# ESP32-H4 register map
Vendor: ESPRESSIF SYSTEMS (SHANGHAI) CO., LTD.; Series: ESP32 H-Series; File version: 1
CPU: RV32IMAC r0p0, little endian, no MPU, no FPU, 0 interrupt priority bits
Address unit: 32 bits
Registers are 32-bit, read-write, reset 0x0 unless marked. A register's access mark holds for its fields unless they carry their own. Offsets are from the block's base; [hi:lo] are bit positions; {n}, {i} and the like mark numbered series.

## SOC_ETM (part 1 of 2) — Event Task Matrix
Base 0x60021000
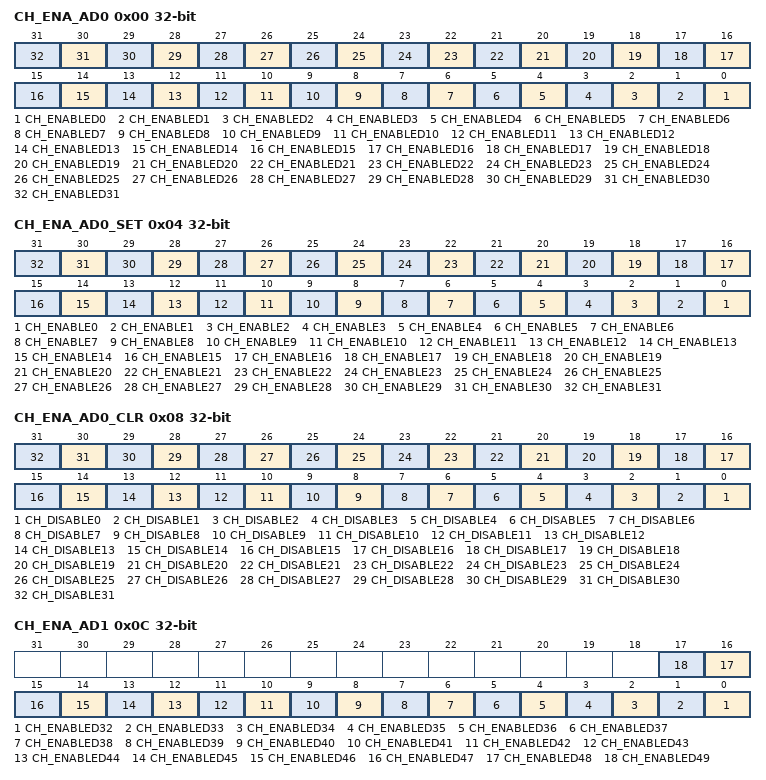
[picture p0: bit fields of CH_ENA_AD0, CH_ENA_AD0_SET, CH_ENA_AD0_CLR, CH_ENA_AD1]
0x00 CH_ENA_AD0 — Channel enable status register
  [n] CH_ENABLED{n} (n=0..31) — Represents ch{n} enable status.\\0: Disable\\1: Enable
0x04 CH_ENA_AD0_SET wo — Channel enable set register
  [n] CH_ENABLE{n} (n=0..31) — Configures whether or not to enable ch{n}.\\0: Invalid, No effect\\1: Enable
0x08 CH_ENA_AD0_CLR wo — Channel enable clear register
  [n] CH_DISABLE{n} (n=0..31) — Configures whether or not to clear ch{n} enable.\\0: Invalid, No effect\\1: Clear
0x0C CH_ENA_AD1 — Channel enable status register
  [n-32] CH_ENABLED{n} (n=32..49) — Represents ch{n} enable status.\\0: Disable\\1: Enable
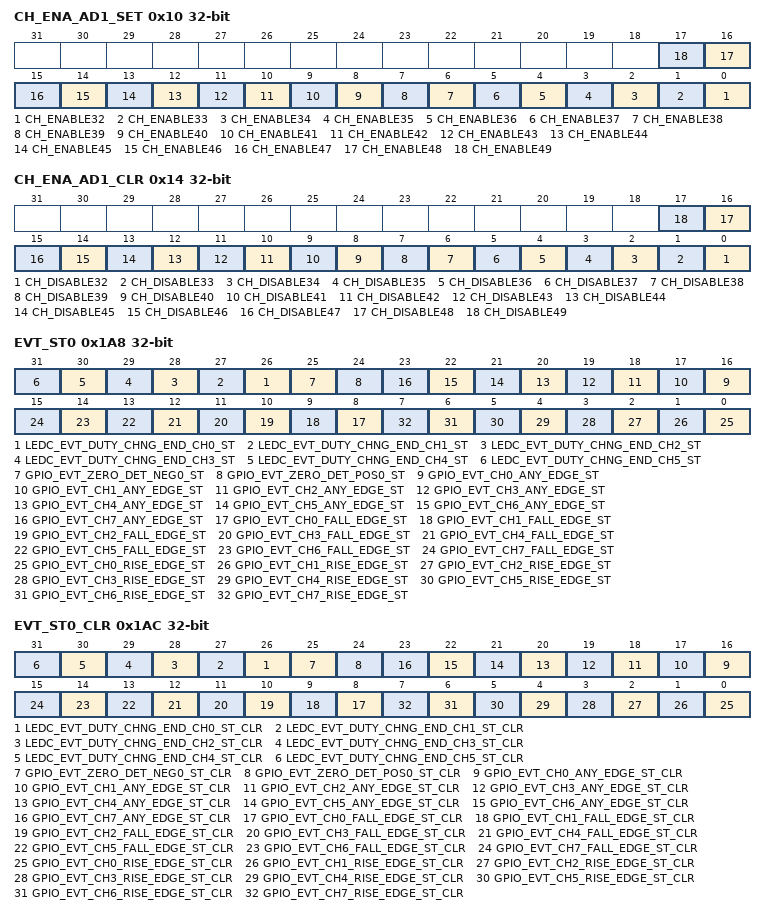
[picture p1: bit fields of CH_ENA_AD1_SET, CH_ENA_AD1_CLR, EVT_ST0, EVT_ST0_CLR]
0x10 CH_ENA_AD1_SET wo — Channel enable set register
  [n-32] CH_ENABLE{n} (n=32..49) — Configures whether or not to enable ch{n}.\\0: Invalid, No effect\\1: Enable
0x14 CH_ENA_AD1_CLR wo — Channel enable clear register
  [n-32] CH_DISABLE{n} (n=32..49) — Configures whether or not to clear ch{n} enable.\\0: Invalid, No effect\\1: Clear
{0x18+8i} CH{i}_EVT_ID (i=0..49) — Channel{i} event id register
  [7:0] CH_EVT_ID — Configures ch%s_evt_id
{0x1C+8i} CH{i}_TASK_ID (i=0..49) — Channel{i} task id register
  [7:0] CH_TASK_ID — Configures ch%s_task_id
0x1A8 EVT_ST0 — Events trigger status register
  [n+26] LEDC_EVT_DUTY_CHNG_END_CH{n}_ST (n=0..5) — Represents LEDC_evt_duty_chng_end_ch{n} trigger status.\\0: Not triggered\\1: Triggered
  [25] GPIO_EVT_ZERO_DET_NEG0_ST — Represents GPIO_evt_zero_det_neg0 trigger status.\\0: Not triggered\\1: Triggered
  [24] GPIO_EVT_ZERO_DET_POS0_ST — Represents GPIO_evt_zero_det_pos0 trigger status.\\0: Not triggered\\1: Triggered
  [n+16] GPIO_EVT_CH{n}_ANY_EDGE_ST (n=0..7) — Represents GPIO_evt_ch{n}_any_edge trigger status.\\0: Not triggered\\1: Triggered
  [n+8] GPIO_EVT_CH{n}_FALL_EDGE_ST (n=0..7) — Represents GPIO_evt_ch{n}_fall_edge trigger status.\\0: Not triggered\\1: Triggered
  [n] GPIO_EVT_CH{n}_RISE_EDGE_ST (n=0..7) — Represents GPIO_evt_ch{n}_rise_edge trigger status.\\0: Not triggered\\1: Triggered
0x1AC EVT_ST0_CLR wo — Events trigger status clear register
  [n+26] LEDC_EVT_DUTY_CHNG_END_CH{n}_ST_CLR (n=0..5) — Configures whether or not to clear LEDC_evt_duty_chng_end_ch{n} trigger status.\\0: Invalid, No effect\\1: Clear
  [25] GPIO_EVT_ZERO_DET_NEG0_ST_CLR — Configures whether or not to clear GPIO_evt_zero_det_neg0 trigger status.\\0: Invalid, No effect\\1: Clear
  [24] GPIO_EVT_ZERO_DET_POS0_ST_CLR — Configures whether or not to clear GPIO_evt_zero_det_pos0 trigger status.\\0: Invalid, No effect\\1: Clear
  [n+16] GPIO_EVT_CH{n}_ANY_EDGE_ST_CLR (n=0..7) — Configures whether or not to clear GPIO_evt_ch{n}_any_edge trigger status.\\0: Invalid, No effect\\1: Clear
  [n+8] GPIO_EVT_CH{n}_FALL_EDGE_ST_CLR (n=0..7) — Configures whether or not to clear GPIO_evt_ch{n}_fall_edge trigger status.\\0: Invalid, No effect\\1: Clear
  [n] GPIO_EVT_CH{n}_RISE_EDGE_ST_CLR (n=0..7) — Configures whether or not to clear GPIO_evt_ch{n}_rise_edge trigger status.\\0: Invalid, No effect\\1: Clear
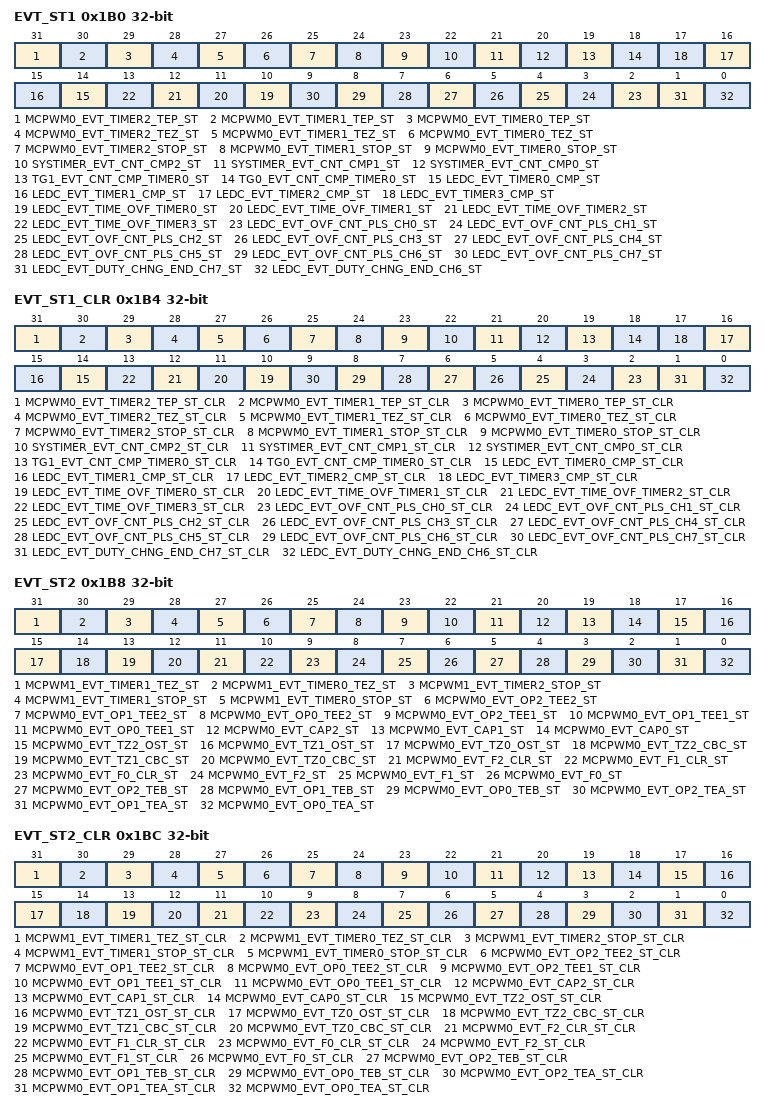
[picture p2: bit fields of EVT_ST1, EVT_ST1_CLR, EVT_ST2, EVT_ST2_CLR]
0x1B0 EVT_ST1 — Events trigger status register
  [31] MCPWM0_EVT_TIMER2_TEP_ST — Represents MCPWM0_evt_timer2_tep trigger status.\\0: Not triggered\\1: Triggered
  [30] MCPWM0_EVT_TIMER1_TEP_ST — Represents MCPWM0_evt_timer1_tep trigger status.\\0: Not triggered\\1: Triggered
  [29] MCPWM0_EVT_TIMER0_TEP_ST — Represents MCPWM0_evt_timer0_tep trigger status.\\0: Not triggered\\1: Triggered
  [28] MCPWM0_EVT_TIMER2_TEZ_ST — Represents MCPWM0_evt_timer2_tez trigger status.\\0: Not triggered\\1: Triggered
  [27] MCPWM0_EVT_TIMER1_TEZ_ST — Represents MCPWM0_evt_timer1_tez trigger status.\\0: Not triggered\\1: Triggered
  [26] MCPWM0_EVT_TIMER0_TEZ_ST — Represents MCPWM0_evt_timer0_tez trigger status.\\0: Not triggered\\1: Triggered
  [25] MCPWM0_EVT_TIMER2_STOP_ST — Represents MCPWM0_evt_timer2_stop trigger status.\\0: Not triggered\\1: Triggered
  [24] MCPWM0_EVT_TIMER1_STOP_ST — Represents MCPWM0_evt_timer1_stop trigger status.\\0: Not triggered\\1: Triggered
  [23] MCPWM0_EVT_TIMER0_STOP_ST — Represents MCPWM0_evt_timer0_stop trigger status.\\0: Not triggered\\1: Triggered
  [22] SYSTIMER_EVT_CNT_CMP2_ST — Represents SYSTIMER_evt_cnt_cmp2 trigger status.\\0: Not triggered\\1: Triggered
  [21] SYSTIMER_EVT_CNT_CMP1_ST — Represents SYSTIMER_evt_cnt_cmp1 trigger status.\\0: Not triggered\\1: Triggered
  [20] SYSTIMER_EVT_CNT_CMP0_ST — Represents SYSTIMER_evt_cnt_cmp0 trigger status.\\0: Not triggered\\1: Triggered
  [19] TG1_EVT_CNT_CMP_TIMER0_ST — Represents TG1_evt_cnt_cmp_timer0 trigger status.\\0: Not triggered\\1: Triggered
  [18] TG0_EVT_CNT_CMP_TIMER0_ST — Represents TG0_evt_cnt_cmp_timer0 trigger status.\\0: Not triggered\\1: Triggered
  [n+14] LEDC_EVT_TIMER{n}_CMP_ST (n=0..3) — Represents LEDC_evt_timer{n}_cmp trigger status.\\0: Not triggered\\1: Triggered
  [n+10] LEDC_EVT_TIME_OVF_TIMER{n}_ST (n=0..3) — Represents LEDC_evt_time_ovf_timer{n} trigger status.\\0: Not triggered\\1: Triggered
  [n+2] LEDC_EVT_OVF_CNT_PLS_CH{n}_ST (n=0..7) — Represents LEDC_evt_ovf_cnt_pls_ch{n} trigger status.\\0: Not triggered\\1: Triggered
  [1] LEDC_EVT_DUTY_CHNG_END_CH7_ST — Represents LEDC_evt_duty_chng_end_ch7 trigger status.\\0: Not triggered\\1: Triggered
  [0] LEDC_EVT_DUTY_CHNG_END_CH6_ST — Represents LEDC_evt_duty_chng_end_ch6 trigger status.\\0: Not triggered\\1: Triggered
0x1B4 EVT_ST1_CLR wo — Events trigger status clear register
  [31] MCPWM0_EVT_TIMER2_TEP_ST_CLR — Configures whether or not to clear MCPWM0_evt_timer2_tep trigger status.\\0: Invalid, No effect\\1: Clear
  [30] MCPWM0_EVT_TIMER1_TEP_ST_CLR — Configures whether or not to clear MCPWM0_evt_timer1_tep trigger status.\\0: Invalid, No effect\\1: Clear
  [29] MCPWM0_EVT_TIMER0_TEP_ST_CLR — Configures whether or not to clear MCPWM0_evt_timer0_tep trigger status.\\0: Invalid, No effect\\1: Clear
  [28] MCPWM0_EVT_TIMER2_TEZ_ST_CLR — Configures whether or not to clear MCPWM0_evt_timer2_tez trigger status.\\0: Invalid, No effect\\1: Clear
  [27] MCPWM0_EVT_TIMER1_TEZ_ST_CLR — Configures whether or not to clear MCPWM0_evt_timer1_tez trigger status.\\0: Invalid, No effect\\1: Clear
  [26] MCPWM0_EVT_TIMER0_TEZ_ST_CLR — Configures whether or not to clear MCPWM0_evt_timer0_tez trigger status.\\0: Invalid, No effect\\1: Clear
  [25] MCPWM0_EVT_TIMER2_STOP_ST_CLR — Configures whether or not to clear MCPWM0_evt_timer2_stop trigger status.\\0: Invalid, No effect\\1: Clear
  [24] MCPWM0_EVT_TIMER1_STOP_ST_CLR — Configures whether or not to clear MCPWM0_evt_timer1_stop trigger status.\\0: Invalid, No effect\\1: Clear
  [23] MCPWM0_EVT_TIMER0_STOP_ST_CLR — Configures whether or not to clear MCPWM0_evt_timer0_stop trigger status.\\0: Invalid, No effect\\1: Clear
  [22] SYSTIMER_EVT_CNT_CMP2_ST_CLR — Configures whether or not to clear SYSTIMER_evt_cnt_cmp2 trigger status.\\0: Invalid, No effect\\1: Clear
  [21] SYSTIMER_EVT_CNT_CMP1_ST_CLR — Configures whether or not to clear SYSTIMER_evt_cnt_cmp1 trigger status.\\0: Invalid, No effect\\1: Clear
  [20] SYSTIMER_EVT_CNT_CMP0_ST_CLR — Configures whether or not to clear SYSTIMER_evt_cnt_cmp0 trigger status.\\0: Invalid, No effect\\1: Clear
  [19] TG1_EVT_CNT_CMP_TIMER0_ST_CLR — Configures whether or not to clear TG1_evt_cnt_cmp_timer0 trigger status.\\0: Invalid, No effect\\1: Clear
  [18] TG0_EVT_CNT_CMP_TIMER0_ST_CLR — Configures whether or not to clear TG0_evt_cnt_cmp_timer0 trigger status.\\0: Invalid, No effect\\1: Clear
  [n+14] LEDC_EVT_TIMER{n}_CMP_ST_CLR (n=0..3) — Configures whether or not to clear LEDC_evt_timer{n}_cmp trigger status.\\0: Invalid, No effect\\1: Clear
  [n+10] LEDC_EVT_TIME_OVF_TIMER{n}_ST_CLR (n=0..3) — Configures whether or not to clear LEDC_evt_time_ovf_timer{n} trigger status.\\0: Invalid, No effect\\1: Clear
  [n+2] LEDC_EVT_OVF_CNT_PLS_CH{n}_ST_CLR (n=0..7) — Configures whether or not to clear LEDC_evt_ovf_cnt_pls_ch{n} trigger status.\\0: Invalid, No effect\\1: Clear
  [1] LEDC_EVT_DUTY_CHNG_END_CH7_ST_CLR — Configures whether or not to clear LEDC_evt_duty_chng_end_ch7 trigger status.\\0: Invalid, No effect\\1: Clear
  [0] LEDC_EVT_DUTY_CHNG_END_CH6_ST_CLR — Configures whether or not to clear LEDC_evt_duty_chng_end_ch6 trigger status.\\0: Invalid, No effect\\1: Clear
0x1B8 EVT_ST2 — Events trigger status register
  [31] MCPWM1_EVT_TIMER1_TEZ_ST — Represents MCPWM1_evt_timer1_tez trigger status.\\0: Not triggered\\1: Triggered
  [30] MCPWM1_EVT_TIMER0_TEZ_ST — Represents MCPWM1_evt_timer0_tez trigger status.\\0: Not triggered\\1: Triggered
  [29] MCPWM1_EVT_TIMER2_STOP_ST — Represents MCPWM1_evt_timer2_stop trigger status.\\0: Not triggered\\1: Triggered
  [28] MCPWM1_EVT_TIMER1_STOP_ST — Represents MCPWM1_evt_timer1_stop trigger status.\\0: Not triggered\\1: Triggered
  [27] MCPWM1_EVT_TIMER0_STOP_ST — Represents MCPWM1_evt_timer0_stop trigger status.\\0: Not triggered\\1: Triggered
  [26] MCPWM0_EVT_OP2_TEE2_ST — Represents MCPWM0_evt_op2_tee2 trigger status.\\0: Not triggered\\1: Triggered
  [25] MCPWM0_EVT_OP1_TEE2_ST — Represents MCPWM0_evt_op1_tee2 trigger status.\\0: Not triggered\\1: Triggered
  [24] MCPWM0_EVT_OP0_TEE2_ST — Represents MCPWM0_evt_op0_tee2 trigger status.\\0: Not triggered\\1: Triggered
  [23] MCPWM0_EVT_OP2_TEE1_ST — Represents MCPWM0_evt_op2_tee1 trigger status.\\0: Not triggered\\1: Triggered
  [22] MCPWM0_EVT_OP1_TEE1_ST — Represents MCPWM0_evt_op1_tee1 trigger status.\\0: Not triggered\\1: Triggered
  [21] MCPWM0_EVT_OP0_TEE1_ST — Represents MCPWM0_evt_op0_tee1 trigger status.\\0: Not triggered\\1: Triggered
  [20] MCPWM0_EVT_CAP2_ST — Represents MCPWM0_evt_cap2 trigger status.\\0: Not triggered\\1: Triggered
  [19] MCPWM0_EVT_CAP1_ST — Represents MCPWM0_evt_cap1 trigger status.\\0: Not triggered\\1: Triggered
  [18] MCPWM0_EVT_CAP0_ST — Represents MCPWM0_evt_cap0 trigger status.\\0: Not triggered\\1: Triggered
  [17] MCPWM0_EVT_TZ2_OST_ST — Represents MCPWM0_evt_tz2_ost trigger status.\\0: Not triggered\\1: Triggered
  [16] MCPWM0_EVT_TZ1_OST_ST — Represents MCPWM0_evt_tz1_ost trigger status.\\0: Not triggered\\1: Triggered
  [15] MCPWM0_EVT_TZ0_OST_ST — Represents MCPWM0_evt_tz0_ost trigger status.\\0: Not triggered\\1: Triggered
  [14] MCPWM0_EVT_TZ2_CBC_ST — Represents MCPWM0_evt_tz2_cbc trigger status.\\0: Not triggered\\1: Triggered
  [13] MCPWM0_EVT_TZ1_CBC_ST — Represents MCPWM0_evt_tz1_cbc trigger status.\\0: Not triggered\\1: Triggered
  [12] MCPWM0_EVT_TZ0_CBC_ST — Represents MCPWM0_evt_tz0_cbc trigger status.\\0: Not triggered\\1: Triggered
  [11] MCPWM0_EVT_F2_CLR_ST — Represents MCPWM0_evt_f2_clr trigger status.\\0: Not triggered\\1: Triggered
  [10] MCPWM0_EVT_F1_CLR_ST — Represents MCPWM0_evt_f1_clr trigger status.\\0: Not triggered\\1: Triggered
  [9] MCPWM0_EVT_F0_CLR_ST — Represents MCPWM0_evt_f0_clr trigger status.\\0: Not triggered\\1: Triggered
  [8] MCPWM0_EVT_F2_ST — Represents MCPWM0_evt_f2 trigger status.\\0: Not triggered\\1: Triggered
  [7] MCPWM0_EVT_F1_ST — Represents MCPWM0_evt_f1 trigger status.\\0: Not triggered\\1: Triggered
  [6] MCPWM0_EVT_F0_ST — Represents MCPWM0_evt_f0 trigger status.\\0: Not triggered\\1: Triggered
  [5] MCPWM0_EVT_OP2_TEB_ST — Represents MCPWM0_evt_op2_teb trigger status.\\0: Not triggered\\1: Triggered
  [4] MCPWM0_EVT_OP1_TEB_ST — Represents MCPWM0_evt_op1_teb trigger status.\\0: Not triggered\\1: Triggered
  [3] MCPWM0_EVT_OP0_TEB_ST — Represents MCPWM0_evt_op0_teb trigger status.\\0: Not triggered\\1: Triggered
  [2] MCPWM0_EVT_OP2_TEA_ST — Represents MCPWM0_evt_op2_tea trigger status.\\0: Not triggered\\1: Triggered
  [1] MCPWM0_EVT_OP1_TEA_ST — Represents MCPWM0_evt_op1_tea trigger status.\\0: Not triggered\\1: Triggered
  [0] MCPWM0_EVT_OP0_TEA_ST — Represents MCPWM0_evt_op0_tea trigger status.\\0: Not triggered\\1: Triggered
0x1BC EVT_ST2_CLR wo — Events trigger status clear register
  [31] MCPWM1_EVT_TIMER1_TEZ_ST_CLR — Configures whether or not to clear MCPWM1_evt_timer1_tez trigger status.\\0: Invalid, No effect\\1: Clear
  [30] MCPWM1_EVT_TIMER0_TEZ_ST_CLR — Configures whether or not to clear MCPWM1_evt_timer0_tez trigger status.\\0: Invalid, No effect\\1: Clear
  [29] MCPWM1_EVT_TIMER2_STOP_ST_CLR — Configures whether or not to clear MCPWM1_evt_timer2_stop trigger status.\\0: Invalid, No effect\\1: Clear
  [28] MCPWM1_EVT_TIMER1_STOP_ST_CLR — Configures whether or not to clear MCPWM1_evt_timer1_stop trigger status.\\0: Invalid, No effect\\1: Clear
  [27] MCPWM1_EVT_TIMER0_STOP_ST_CLR — Configures whether or not to clear MCPWM1_evt_timer0_stop trigger status.\\0: Invalid, No effect\\1: Clear
  [26] MCPWM0_EVT_OP2_TEE2_ST_CLR — Configures whether or not to clear MCPWM0_evt_op2_tee2 trigger status.\\0: Invalid, No effect\\1: Clear
  [25] MCPWM0_EVT_OP1_TEE2_ST_CLR — Configures whether or not to clear MCPWM0_evt_op1_tee2 trigger status.\\0: Invalid, No effect\\1: Clear
  [24] MCPWM0_EVT_OP0_TEE2_ST_CLR — Configures whether or not to clear MCPWM0_evt_op0_tee2 trigger status.\\0: Invalid, No effect\\1: Clear
  [23] MCPWM0_EVT_OP2_TEE1_ST_CLR — Configures whether or not to clear MCPWM0_evt_op2_tee1 trigger status.\\0: Invalid, No effect\\1: Clear
  [22] MCPWM0_EVT_OP1_TEE1_ST_CLR — Configures whether or not to clear MCPWM0_evt_op1_tee1 trigger status.\\0: Invalid, No effect\\1: Clear
  [21] MCPWM0_EVT_OP0_TEE1_ST_CLR — Configures whether or not to clear MCPWM0_evt_op0_tee1 trigger status.\\0: Invalid, No effect\\1: Clear
  [20] MCPWM0_EVT_CAP2_ST_CLR — Configures whether or not to clear MCPWM0_evt_cap2 trigger status.\\0: Invalid, No effect\\1: Clear
  [19] MCPWM0_EVT_CAP1_ST_CLR — Configures whether or not to clear MCPWM0_evt_cap1 trigger status.\\0: Invalid, No effect\\1: Clear
  [18] MCPWM0_EVT_CAP0_ST_CLR — Configures whether or not to clear MCPWM0_evt_cap0 trigger status.\\0: Invalid, No effect\\1: Clear
  [17] MCPWM0_EVT_TZ2_OST_ST_CLR — Configures whether or not to clear MCPWM0_evt_tz2_ost trigger status.\\0: Invalid, No effect\\1: Clear
  [16] MCPWM0_EVT_TZ1_OST_ST_CLR — Configures whether or not to clear MCPWM0_evt_tz1_ost trigger status.\\0: Invalid, No effect\\1: Clear
  [15] MCPWM0_EVT_TZ0_OST_ST_CLR — Configures whether or not to clear MCPWM0_evt_tz0_ost trigger status.\\0: Invalid, No effect\\1: Clear
  [14] MCPWM0_EVT_TZ2_CBC_ST_CLR — Configures whether or not to clear MCPWM0_evt_tz2_cbc trigger status.\\0: Invalid, No effect\\1: Clear
  [13] MCPWM0_EVT_TZ1_CBC_ST_CLR — Configures whether or not to clear MCPWM0_evt_tz1_cbc trigger status.\\0: Invalid, No effect\\1: Clear
  [12] MCPWM0_EVT_TZ0_CBC_ST_CLR — Configures whether or not to clear MCPWM0_evt_tz0_cbc trigger status.\\0: Invalid, No effect\\1: Clear
  [11] MCPWM0_EVT_F2_CLR_ST_CLR — Configures whether or not to clear MCPWM0_evt_f2_clr trigger status.\\0: Invalid, No effect\\1: Clear
  [10] MCPWM0_EVT_F1_CLR_ST_CLR — Configures whether or not to clear MCPWM0_evt_f1_clr trigger status.\\0: Invalid, No effect\\1: Clear
  [9] MCPWM0_EVT_F0_CLR_ST_CLR — Configures whether or not to clear MCPWM0_evt_f0_clr trigger status.\\0: Invalid, No effect\\1: Clear
  [8] MCPWM0_EVT_F2_ST_CLR — Configures whether or not to clear MCPWM0_evt_f2 trigger status.\\0: Invalid, No effect\\1: Clear
  [7] MCPWM0_EVT_F1_ST_CLR — Configures whether or not to clear MCPWM0_evt_f1 trigger status.\\0: Invalid, No effect\\1: Clear
  [6] MCPWM0_EVT_F0_ST_CLR — Configures whether or not to clear MCPWM0_evt_f0 trigger status.\\0: Invalid, No effect\\1: Clear
  [5] MCPWM0_EVT_OP2_TEB_ST_CLR — Configures whether or not to clear MCPWM0_evt_op2_teb trigger status.\\0: Invalid, No effect\\1: Clear
  [4] MCPWM0_EVT_OP1_TEB_ST_CLR — Configures whether or not to clear MCPWM0_evt_op1_teb trigger status.\\0: Invalid, No effect\\1: Clear
  [3] MCPWM0_EVT_OP0_TEB_ST_CLR — Configures whether or not to clear MCPWM0_evt_op0_teb trigger status.\\0: Invalid, No effect\\1: Clear
  [2] MCPWM0_EVT_OP2_TEA_ST_CLR — Configures whether or not to clear MCPWM0_evt_op2_tea trigger status.\\0: Invalid, No effect\\1: Clear
  [1] MCPWM0_EVT_OP1_TEA_ST_CLR — Configures whether or not to clear MCPWM0_evt_op1_tea trigger status.\\0: Invalid, No effect\\1: Clear
  [0] MCPWM0_EVT_OP0_TEA_ST_CLR — Configures whether or not to clear MCPWM0_evt_op0_tea trigger status.\\0: Invalid, No effect\\1: Clear
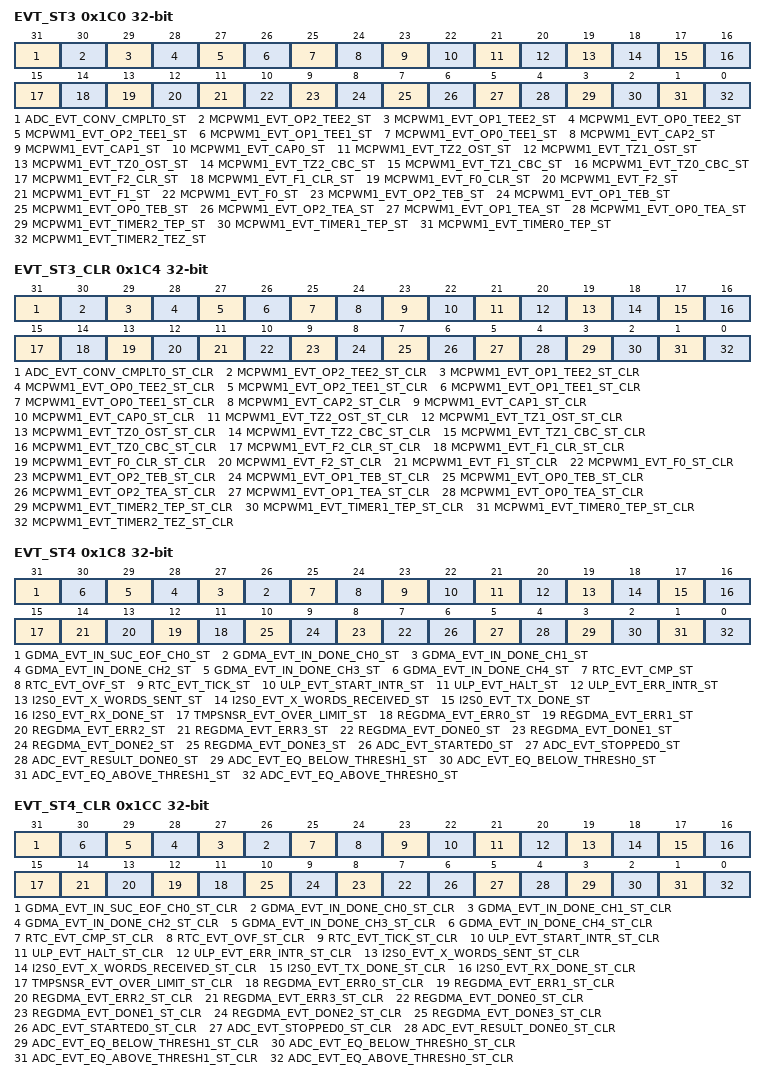
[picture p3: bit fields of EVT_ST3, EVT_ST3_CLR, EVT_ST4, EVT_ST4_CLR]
0x1C0 EVT_ST3 — Events trigger status register
  [31] ADC_EVT_CONV_CMPLT0_ST — Represents ADC_evt_conv_cmplt0 trigger status.\\0: Not triggered\\1: Triggered
  [30] MCPWM1_EVT_OP2_TEE2_ST — Represents MCPWM1_evt_op2_tee2 trigger status.\\0: Not triggered\\1: Triggered
  [29] MCPWM1_EVT_OP1_TEE2_ST — Represents MCPWM1_evt_op1_tee2 trigger status.\\0: Not triggered\\1: Triggered
  [28] MCPWM1_EVT_OP0_TEE2_ST — Represents MCPWM1_evt_op0_tee2 trigger status.\\0: Not triggered\\1: Triggered
  [27] MCPWM1_EVT_OP2_TEE1_ST — Represents MCPWM1_evt_op2_tee1 trigger status.\\0: Not triggered\\1: Triggered
  [26] MCPWM1_EVT_OP1_TEE1_ST — Represents MCPWM1_evt_op1_tee1 trigger status.\\0: Not triggered\\1: Triggered
  [25] MCPWM1_EVT_OP0_TEE1_ST — Represents MCPWM1_evt_op0_tee1 trigger status.\\0: Not triggered\\1: Triggered
  [24] MCPWM1_EVT_CAP2_ST — Represents MCPWM1_evt_cap2 trigger status.\\0: Not triggered\\1: Triggered
  [23] MCPWM1_EVT_CAP1_ST — Represents MCPWM1_evt_cap1 trigger status.\\0: Not triggered\\1: Triggered
  [22] MCPWM1_EVT_CAP0_ST — Represents MCPWM1_evt_cap0 trigger status.\\0: Not triggered\\1: Triggered
  [21] MCPWM1_EVT_TZ2_OST_ST — Represents MCPWM1_evt_tz2_ost trigger status.\\0: Not triggered\\1: Triggered
  [20] MCPWM1_EVT_TZ1_OST_ST — Represents MCPWM1_evt_tz1_ost trigger status.\\0: Not triggered\\1: Triggered
  [19] MCPWM1_EVT_TZ0_OST_ST — Represents MCPWM1_evt_tz0_ost trigger status.\\0: Not triggered\\1: Triggered
  [18] MCPWM1_EVT_TZ2_CBC_ST — Represents MCPWM1_evt_tz2_cbc trigger status.\\0: Not triggered\\1: Triggered
  [17] MCPWM1_EVT_TZ1_CBC_ST — Represents MCPWM1_evt_tz1_cbc trigger status.\\0: Not triggered\\1: Triggered
  [16] MCPWM1_EVT_TZ0_CBC_ST — Represents MCPWM1_evt_tz0_cbc trigger status.\\0: Not triggered\\1: Triggered
  [15] MCPWM1_EVT_F2_CLR_ST — Represents MCPWM1_evt_f2_clr trigger status.\\0: Not triggered\\1: Triggered
  [14] MCPWM1_EVT_F1_CLR_ST — Represents MCPWM1_evt_f1_clr trigger status.\\0: Not triggered\\1: Triggered
  [13] MCPWM1_EVT_F0_CLR_ST — Represents MCPWM1_evt_f0_clr trigger status.\\0: Not triggered\\1: Triggered
  [12] MCPWM1_EVT_F2_ST — Represents MCPWM1_evt_f2 trigger status.\\0: Not triggered\\1: Triggered
  [11] MCPWM1_EVT_F1_ST — Represents MCPWM1_evt_f1 trigger status.\\0: Not triggered\\1: Triggered
  [10] MCPWM1_EVT_F0_ST — Represents MCPWM1_evt_f0 trigger status.\\0: Not triggered\\1: Triggered
  [9] MCPWM1_EVT_OP2_TEB_ST — Represents MCPWM1_evt_op2_teb trigger status.\\0: Not triggered\\1: Triggered
  [8] MCPWM1_EVT_OP1_TEB_ST — Represents MCPWM1_evt_op1_teb trigger status.\\0: Not triggered\\1: Triggered
  [7] MCPWM1_EVT_OP0_TEB_ST — Represents MCPWM1_evt_op0_teb trigger status.\\0: Not triggered\\1: Triggered
  [6] MCPWM1_EVT_OP2_TEA_ST — Represents MCPWM1_evt_op2_tea trigger status.\\0: Not triggered\\1: Triggered
  [5] MCPWM1_EVT_OP1_TEA_ST — Represents MCPWM1_evt_op1_tea trigger status.\\0: Not triggered\\1: Triggered
  [4] MCPWM1_EVT_OP0_TEA_ST — Represents MCPWM1_evt_op0_tea trigger status.\\0: Not triggered\\1: Triggered
  [3] MCPWM1_EVT_TIMER2_TEP_ST — Represents MCPWM1_evt_timer2_tep trigger status.\\0: Not triggered\\1: Triggered
  [2] MCPWM1_EVT_TIMER1_TEP_ST — Represents MCPWM1_evt_timer1_tep trigger status.\\0: Not triggered\\1: Triggered
  [1] MCPWM1_EVT_TIMER0_TEP_ST — Represents MCPWM1_evt_timer0_tep trigger status.\\0: Not triggered\\1: Triggered
  [0] MCPWM1_EVT_TIMER2_TEZ_ST — Represents MCPWM1_evt_timer2_tez trigger status.\\0: Not triggered\\1: Triggered
0x1C4 EVT_ST3_CLR wo — Events trigger status clear register
  [31] ADC_EVT_CONV_CMPLT0_ST_CLR — Configures whether or not to clear ADC_evt_conv_cmplt0 trigger status.\\0: Invalid, No effect\\1: Clear
  [30] MCPWM1_EVT_OP2_TEE2_ST_CLR — Configures whether or not to clear MCPWM1_evt_op2_tee2 trigger status.\\0: Invalid, No effect\\1: Clear
  [29] MCPWM1_EVT_OP1_TEE2_ST_CLR — Configures whether or not to clear MCPWM1_evt_op1_tee2 trigger status.\\0: Invalid, No effect\\1: Clear
  [28] MCPWM1_EVT_OP0_TEE2_ST_CLR — Configures whether or not to clear MCPWM1_evt_op0_tee2 trigger status.\\0: Invalid, No effect\\1: Clear
  [27] MCPWM1_EVT_OP2_TEE1_ST_CLR — Configures whether or not to clear MCPWM1_evt_op2_tee1 trigger status.\\0: Invalid, No effect\\1: Clear
  [26] MCPWM1_EVT_OP1_TEE1_ST_CLR — Configures whether or not to clear MCPWM1_evt_op1_tee1 trigger status.\\0: Invalid, No effect\\1: Clear
  [25] MCPWM1_EVT_OP0_TEE1_ST_CLR — Configures whether or not to clear MCPWM1_evt_op0_tee1 trigger status.\\0: Invalid, No effect\\1: Clear
  [24] MCPWM1_EVT_CAP2_ST_CLR — Configures whether or not to clear MCPWM1_evt_cap2 trigger status.\\0: Invalid, No effect\\1: Clear
  [23] MCPWM1_EVT_CAP1_ST_CLR — Configures whether or not to clear MCPWM1_evt_cap1 trigger status.\\0: Invalid, No effect\\1: Clear
  [22] MCPWM1_EVT_CAP0_ST_CLR — Configures whether or not to clear MCPWM1_evt_cap0 trigger status.\\0: Invalid, No effect\\1: Clear
  [21] MCPWM1_EVT_TZ2_OST_ST_CLR — Configures whether or not to clear MCPWM1_evt_tz2_ost trigger status.\\0: Invalid, No effect\\1: Clear
  [20] MCPWM1_EVT_TZ1_OST_ST_CLR — Configures whether or not to clear MCPWM1_evt_tz1_ost trigger status.\\0: Invalid, No effect\\1: Clear
  [19] MCPWM1_EVT_TZ0_OST_ST_CLR — Configures whether or not to clear MCPWM1_evt_tz0_ost trigger status.\\0: Invalid, No effect\\1: Clear
  [18] MCPWM1_EVT_TZ2_CBC_ST_CLR — Configures whether or not to clear MCPWM1_evt_tz2_cbc trigger status.\\0: Invalid, No effect\\1: Clear
  [17] MCPWM1_EVT_TZ1_CBC_ST_CLR — Configures whether or not to clear MCPWM1_evt_tz1_cbc trigger status.\\0: Invalid, No effect\\1: Clear
  [16] MCPWM1_EVT_TZ0_CBC_ST_CLR — Configures whether or not to clear MCPWM1_evt_tz0_cbc trigger status.\\0: Invalid, No effect\\1: Clear
  [15] MCPWM1_EVT_F2_CLR_ST_CLR — Configures whether or not to clear MCPWM1_evt_f2_clr trigger status.\\0: Invalid, No effect\\1: Clear
  [14] MCPWM1_EVT_F1_CLR_ST_CLR — Configures whether or not to clear MCPWM1_evt_f1_clr trigger status.\\0: Invalid, No effect\\1: Clear
  [13] MCPWM1_EVT_F0_CLR_ST_CLR — Configures whether or not to clear MCPWM1_evt_f0_clr trigger status.\\0: Invalid, No effect\\1: Clear
  [12] MCPWM1_EVT_F2_ST_CLR — Configures whether or not to clear MCPWM1_evt_f2 trigger status.\\0: Invalid, No effect\\1: Clear
  [11] MCPWM1_EVT_F1_ST_CLR — Configures whether or not to clear MCPWM1_evt_f1 trigger status.\\0: Invalid, No effect\\1: Clear
  [10] MCPWM1_EVT_F0_ST_CLR — Configures whether or not to clear MCPWM1_evt_f0 trigger status.\\0: Invalid, No effect\\1: Clear
  [9] MCPWM1_EVT_OP2_TEB_ST_CLR — Configures whether or not to clear MCPWM1_evt_op2_teb trigger status.\\0: Invalid, No effect\\1: Clear
  [8] MCPWM1_EVT_OP1_TEB_ST_CLR — Configures whether or not to clear MCPWM1_evt_op1_teb trigger status.\\0: Invalid, No effect\\1: Clear
  [7] MCPWM1_EVT_OP0_TEB_ST_CLR — Configures whether or not to clear MCPWM1_evt_op0_teb trigger status.\\0: Invalid, No effect\\1: Clear
  [6] MCPWM1_EVT_OP2_TEA_ST_CLR — Configures whether or not to clear MCPWM1_evt_op2_tea trigger status.\\0: Invalid, No effect\\1: Clear
  [5] MCPWM1_EVT_OP1_TEA_ST_CLR — Configures whether or not to clear MCPWM1_evt_op1_tea trigger status.\\0: Invalid, No effect\\1: Clear
  [4] MCPWM1_EVT_OP0_TEA_ST_CLR — Configures whether or not to clear MCPWM1_evt_op0_tea trigger status.\\0: Invalid, No effect\\1: Clear
  [3] MCPWM1_EVT_TIMER2_TEP_ST_CLR — Configures whether or not to clear MCPWM1_evt_timer2_tep trigger status.\\0: Invalid, No effect\\1: Clear
  [2] MCPWM1_EVT_TIMER1_TEP_ST_CLR — Configures whether or not to clear MCPWM1_evt_timer1_tep trigger status.\\0: Invalid, No effect\\1: Clear
  [1] MCPWM1_EVT_TIMER0_TEP_ST_CLR — Configures whether or not to clear MCPWM1_evt_timer0_tep trigger status.\\0: Invalid, No effect\\1: Clear
  [0] MCPWM1_EVT_TIMER2_TEZ_ST_CLR — Configures whether or not to clear MCPWM1_evt_timer2_tez trigger status.\\0: Invalid, No effect\\1: Clear
0x1C8 EVT_ST4 — Events trigger status register
  [31] GDMA_EVT_IN_SUC_EOF_CH0_ST — Represents GDMA_evt_in_suc_eof_ch0 trigger status.\\0: Not triggered\\1: Triggered
  [n+26] GDMA_EVT_IN_DONE_CH{n}_ST (n=0..4) — Represents GDMA_evt_in_done_ch{n} trigger status.\\0: Not triggered\\1: Triggered
  [25] RTC_EVT_CMP_ST — Represents RTC_evt_cmp trigger status.\\0: Not triggered\\1: Triggered
  [24] RTC_EVT_OVF_ST — Represents RTC_evt_ovf trigger status.\\0: Not triggered\\1: Triggered
  [23] RTC_EVT_TICK_ST — Represents RTC_evt_tick trigger status.\\0: Not triggered\\1: Triggered
  [22] ULP_EVT_START_INTR_ST — Represents ULP_evt_start_intr trigger status.\\0: Not triggered\\1: Triggered
  [21] ULP_EVT_HALT_ST — Represents ULP_evt_halt trigger status.\\0: Not triggered\\1: Triggered
  [20] ULP_EVT_ERR_INTR_ST — Represents ULP_evt_err_intr trigger status.\\0: Not triggered\\1: Triggered
  [19] I2S0_EVT_X_WORDS_SENT_ST — Represents I2S0_evt_x_words_sent trigger status.\\0: Not triggered\\1: Triggered
  [18] I2S0_EVT_X_WORDS_RECEIVED_ST — Represents I2S0_evt_x_words_received trigger status.\\0: Not triggered\\1: Triggered
  [17] I2S0_EVT_TX_DONE_ST — Represents I2S0_evt_tx_done trigger status.\\0: Not triggered\\1: Triggered
  [16] I2S0_EVT_RX_DONE_ST — Represents I2S0_evt_rx_done trigger status.\\0: Not triggered\\1: Triggered
  [15] TMPSNSR_EVT_OVER_LIMIT_ST — Represents TMPSNSR_evt_over_limit trigger status.\\0: Not triggered\\1: Triggered
  [n+11] REGDMA_EVT_ERR{n}_ST (n=0..3) — Represents REGDMA_evt_err{n} trigger status.\\0: Not triggered\\1: Triggered
  [n+7] REGDMA_EVT_DONE{n}_ST (n=0..3) — Represents REGDMA_evt_done{n} trigger status.\\0: Not triggered\\1: Triggered
  [6] ADC_EVT_STARTED0_ST — Represents ADC_evt_started0 trigger status.\\0: Not triggered\\1: Triggered
  [5] ADC_EVT_STOPPED0_ST — Represents ADC_evt_stopped0 trigger status.\\0: Not triggered\\1: Triggered
  [4] ADC_EVT_RESULT_DONE0_ST — Represents ADC_evt_result_done0 trigger status.\\0: Not triggered\\1: Triggered
  [3] ADC_EVT_EQ_BELOW_THRESH1_ST — Represents ADC_evt_eq_below_thresh1 trigger status.\\0: Not triggered\\1: Triggered
  [2] ADC_EVT_EQ_BELOW_THRESH0_ST — Represents ADC_evt_eq_below_thresh0 trigger status.\\0: Not triggered\\1: Triggered
  [1] ADC_EVT_EQ_ABOVE_THRESH1_ST — Represents ADC_evt_eq_above_thresh1 trigger status.\\0: Not triggered\\1: Triggered
  [0] ADC_EVT_EQ_ABOVE_THRESH0_ST — Represents ADC_evt_eq_above_thresh0 trigger status.\\0: Not triggered\\1: Triggered
0x1CC EVT_ST4_CLR wo — Events trigger status clear register
  [31] GDMA_EVT_IN_SUC_EOF_CH0_ST_CLR — Configures whether or not to clear GDMA_evt_in_suc_eof_ch0 trigger status.\\0: Invalid, No effect\\1: Clear
  [n+26] GDMA_EVT_IN_DONE_CH{n}_ST_CLR (n=0..4) — Configures whether or not to clear GDMA_evt_in_done_ch{n} trigger status.\\0: Invalid, No effect\\1: Clear
  [25] RTC_EVT_CMP_ST_CLR — Configures whether or not to clear RTC_evt_cmp trigger status.\\0: Invalid, No effect\\1: Clear
  [24] RTC_EVT_OVF_ST_CLR — Configures whether or not to clear RTC_evt_ovf trigger status.\\0: Invalid, No effect\\1: Clear
  [23] RTC_EVT_TICK_ST_CLR — Configures whether or not to clear RTC_evt_tick trigger status.\\0: Invalid, No effect\\1: Clear
  [22] ULP_EVT_START_INTR_ST_CLR — Configures whether or not to clear ULP_evt_start_intr trigger status.\\0: Invalid, No effect\\1: Clear
  [21] ULP_EVT_HALT_ST_CLR — Configures whether or not to clear ULP_evt_halt trigger status.\\0: Invalid, No effect\\1: Clear
  [20] ULP_EVT_ERR_INTR_ST_CLR — Configures whether or not to clear ULP_evt_err_intr trigger status.\\0: Invalid, No effect\\1: Clear
  [19] I2S0_EVT_X_WORDS_SENT_ST_CLR — Configures whether or not to clear I2S0_evt_x_words_sent trigger status.\\0: Invalid, No effect\\1: Clear
  [18] I2S0_EVT_X_WORDS_RECEIVED_ST_CLR — Configures whether or not to clear I2S0_evt_x_words_received trigger status.\\0: Invalid, No effect\\1: Clear
  [17] I2S0_EVT_TX_DONE_ST_CLR — Configures whether or not to clear I2S0_evt_tx_done trigger status.\\0: Invalid, No effect\\1: Clear
  [16] I2S0_EVT_RX_DONE_ST_CLR — Configures whether or not to clear I2S0_evt_rx_done trigger status.\\0: Invalid, No effect\\1: Clear
  [15] TMPSNSR_EVT_OVER_LIMIT_ST_CLR — Configures whether or not to clear TMPSNSR_evt_over_limit trigger status.\\0: Invalid, No effect\\1: Clear
  [n+11] REGDMA_EVT_ERR{n}_ST_CLR (n=0..3) — Configures whether or not to clear REGDMA_evt_err{n} trigger status.\\0: Invalid, No effect\\1: Clear
  [n+7] REGDMA_EVT_DONE{n}_ST_CLR (n=0..3) — Configures whether or not to clear REGDMA_evt_done{n} trigger status.\\0: Invalid, No effect\\1: Clear
  [6] ADC_EVT_STARTED0_ST_CLR — Configures whether or not to clear ADC_evt_started0 trigger status.\\0: Invalid, No effect\\1: Clear
  [5] ADC_EVT_STOPPED0_ST_CLR — Configures whether or not to clear ADC_evt_stopped0 trigger status.\\0: Invalid, No effect\\1: Clear
  [4] ADC_EVT_RESULT_DONE0_ST_CLR — Configures whether or not to clear ADC_evt_result_done0 trigger status.\\0: Invalid, No effect\\1: Clear
  [3] ADC_EVT_EQ_BELOW_THRESH1_ST_CLR — Configures whether or not to clear ADC_evt_eq_below_thresh1 trigger status.\\0: Invalid, No effect\\1: Clear
  [2] ADC_EVT_EQ_BELOW_THRESH0_ST_CLR — Configures whether or not to clear ADC_evt_eq_below_thresh0 trigger status.\\0: Invalid, No effect\\1: Clear
  [1] ADC_EVT_EQ_ABOVE_THRESH1_ST_CLR — Configures whether or not to clear ADC_evt_eq_above_thresh1 trigger status.\\0: Invalid, No effect\\1: Clear
  [0] ADC_EVT_EQ_ABOVE_THRESH0_ST_CLR — Configures whether or not to clear ADC_evt_eq_above_thresh0 trigger status.\\0: Invalid, No effect\\1: Clear
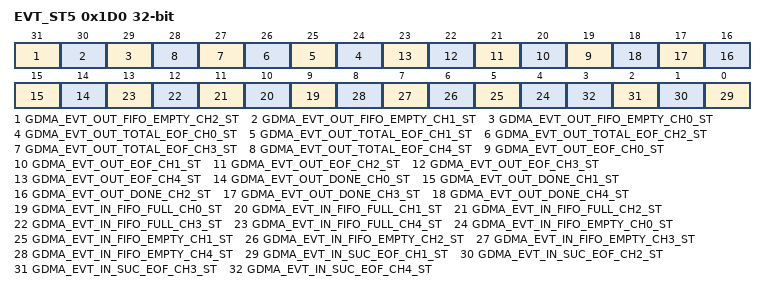
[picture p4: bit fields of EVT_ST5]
0x1D0 EVT_ST5 — Events trigger status register
  [31] GDMA_EVT_OUT_FIFO_EMPTY_CH2_ST — Represents GDMA_evt_out_fifo_empty_ch2 trigger status.\\0: Not triggered\\1: Triggered
  [30] GDMA_EVT_OUT_FIFO_EMPTY_CH1_ST — Represents GDMA_evt_out_fifo_empty_ch1 trigger status.\\0: Not triggered\\1: Triggered
  [29] GDMA_EVT_OUT_FIFO_EMPTY_CH0_ST — Represents GDMA_evt_out_fifo_empty_ch0 trigger status.\\0: Not triggered\\1: Triggered
  [n+24] GDMA_EVT_OUT_TOTAL_EOF_CH{n}_ST (n=0..4) — Represents GDMA_evt_out_total_eof_ch{n} trigger status.\\0: Not triggered\\1: Triggered
  [n+19] GDMA_EVT_OUT_EOF_CH{n}_ST (n=0..4) — Represents GDMA_evt_out_eof_ch{n} trigger status.\\0: Not triggered\\1: Triggered
  [n+14] GDMA_EVT_OUT_DONE_CH{n}_ST (n=0..4) — Represents GDMA_evt_out_done_ch{n} trigger status.\\0: Not triggered\\1: Triggered
  [n+9] GDMA_EVT_IN_FIFO_FULL_CH{n}_ST (n=0..4) — Represents GDMA_evt_in_fifo_full_ch{n} trigger status.\\0: Not triggered\\1: Triggered
  [n+4] GDMA_EVT_IN_FIFO_EMPTY_CH{n}_ST (n=0..4) — Represents GDMA_evt_in_fifo_empty_ch{n} trigger status.\\0: Not triggered\\1: Triggered
  [n-1] GDMA_EVT_IN_SUC_EOF_CH{n}_ST (n=1..4) — Represents GDMA_evt_in_suc_eof_ch{n} trigger status.\\0: Not triggered\\1: Triggered
